# GD32H77x_78x register map
File version: 1.0
CPU: CM7 r1p2, little endian, MPU, FPU, 4 interrupt priority bits
Registers are 32-bit, read-write, reset 0x0 unless marked. A register's access mark holds for its fields unless they carry their own. Offsets are from the block's base; [hi:lo] are bit positions; {n}, {i} and the like mark numbered series.

## DBG — Debug
Base 0xE00E1000
0x00 ID ro — ID code register
  [31:0] ID_CODE — DBG ID code register
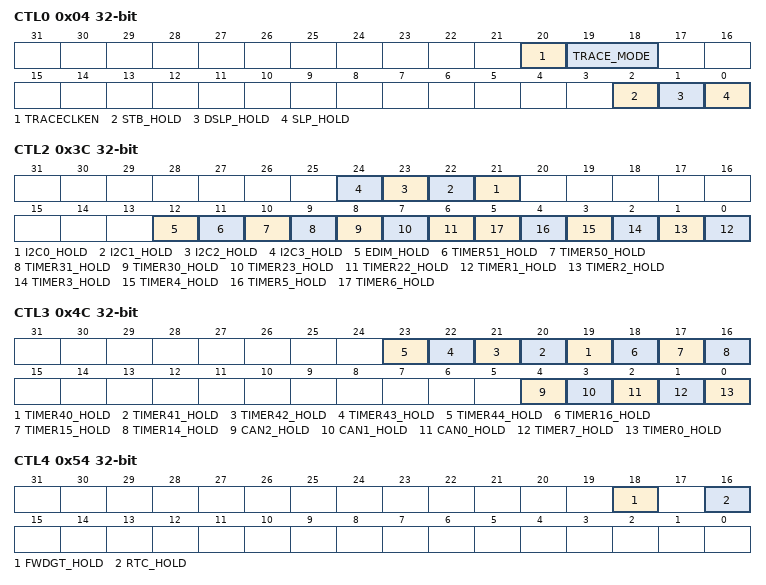
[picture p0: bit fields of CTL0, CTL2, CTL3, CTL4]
0x04 CTL0 — Control register0
  [20] TRACECLKEN — Trace port clock enable
  [19:18] TRACE_MODE — Trace pin allocation mode
  [2] STB_HOLD — Standby mode hold bit
  [1] DSLP_HOLD — Deep-sleep mode hold bit
  [0] SLP_HOLD — Sleep mode hold bit
0x34 CTL1 — Control register1
  [6] WWDGT_HOLD — WWDGT hold bit
0x3C CTL2 — Control register2
  [n+21] I2C{n}_HOLD (n=0..3) — I2C{n} hold bit
  [12] EDIM_HOLD — EDIM hold bit
  [11] TIMER51_HOLD — TIMER51 hold bit
  [10] TIMER50_HOLD — TIMER50 hold bit
  [9] TIMER31_HOLD — TIMER31 hold bit
  [8] TIMER30_HOLD — TIMER30 hold bit
  [7] TIMER23_HOLD — TIMER23 hold bit
  [6] TIMER22_HOLD — TIMER22 hold bit
  [n-1] TIMER{n}_HOLD (n=1..6) — TIMER{n} hold bit
0x4C CTL3 — Control register3
  [n-21] TIMER{n}_HOLD (n=40..44) — TIMER{n} hold bit
  [18] TIMER16_HOLD — TIMER16 hold bit
  [17] TIMER15_HOLD — TIMER15 hold bit
  [16] TIMER14_HOLD — TIMER14 hold bit
  [4] CAN2_HOLD — CAN2 hold bit
  [3] CAN1_HOLD — CAN1 hold bit
  [2] CAN0_HOLD — CAN0 hold bit
  [1] TIMER7_HOLD — TIMER7 hold bit
  [0] TIMER0_HOLD — TIMER0 hold bit
0x54 CTL4 — Control register4
  [18] FWDGT_HOLD — FWDGT hold bit
  [16] RTC_HOLD — RTC hold bit

## DCI — Digital Camera Interface
Base 0x48020000
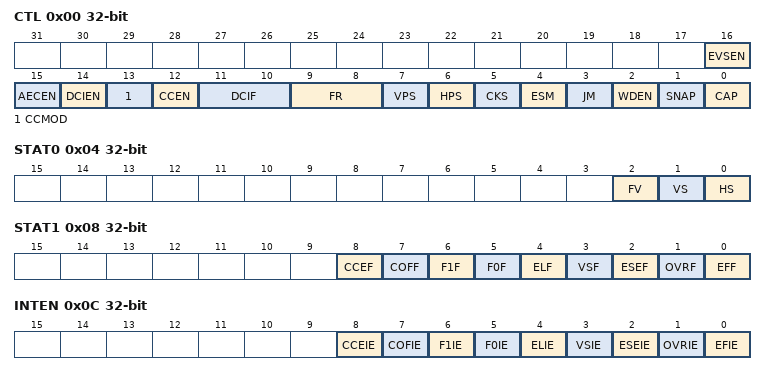
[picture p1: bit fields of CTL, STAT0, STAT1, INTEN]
0x00 CTL — Control register
  [16] EVSEN — External vsync enable
  [15] AECEN — Automatic error correction enable
  [14] DCIEN — DCI Enable
  [13] CCMOD — CCIR mode select
  [12] CCEN — CCIR enable
  [11:10] DCIF — Digital camera interface format
  [9:8] FR — Frame rate
  [7] VPS — Vertical Polarity Selection
  [6] HPS — Horizontal Polarity Selection
  [5] CKS — Clock Polarity Selection
  [4] ESM — Embedded Synchronous Mode
  [3] JM — JPEG mode
  [2] WDEN — Window Enable
  [1] SNAP — Snapshot mode
  [0] CAP — Capture Enable
0x04 STAT0 ro — Status register 0
  [2] FV — FIFO Valid
  [1] VS — VS line status
  [0] HS — HS line status
0x08 STAT1 ro — Status register 1
  [8] CCEF — CCIR error flag
  [7] COFF — CCIR change of field flag
  [6] F1F — CCIR field 1
  [5] F0F — CCIR field 0
  [4] ELF — End of Line Flag
  [3] VSF — Vsync Flag
  [2] ESEF — Embedded Synchronous Error Flag
  [1] OVRF — FIFO Overrun Flag
  [0] EFF — End of Frame Flag
0x0C INTEN — Interrupt enable register
  [8] CCEIE — CCIR error Interrupt enable
  [7] COFIE — CCIR change of field interrupt enable
  [6] F1IE — CCIR field 1 interrupt enable
  [5] F0IE — CCIR field 0 interrupt enable
  [4] ELIE — End of Line Interrupt Enable
  [3] VSIE — Vsync Interrupt Enable
  [2] ESEIE — Embedded Synchronous Error Interrupt Enable
  [1] OVRIE — FIFO Overrun Interrupt Enable
  [0] EFIE — End of Frame Interrupt Enable
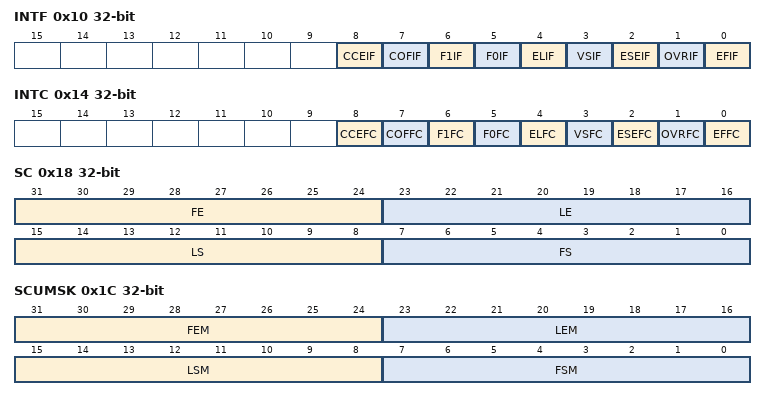
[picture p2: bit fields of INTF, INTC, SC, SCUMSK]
0x10 INTF ro — Interrupt flag register
  [8] CCEIF — CCIR error interrupt flag
  [7] COFIF — CCIR change of field interrupt flag
  [6] F1IF — CCIR field 1 interrupt flag
  [5] F0IF — CCIR field 0 interrupt flag
  [4] ELIF — End of Line Interrupt Flag
  [3] VSIF — Vsync Interrupt Flag
  [2] ESEIF — Embedded Synchronous Error Interrupt Flag
  [1] OVRIF — FIFO Overrun Interrupt Flag
  [0] EFIF — End of Frame Interrupt Flag
0x14 INTC wo — Interrupt flag clear register
  [8] CCEFC — CCIR error flag clear
  [7] COFFC — CCIR change of field flag clear
  [6] F1FC — CCIR field 1 interrupt flag clear
  [5] F0FC — CCIR field 0 interrupt flag clear
  [4] ELFC — End of Line Flag Clear
  [3] VSFC — Vsync flag clear
  [2] ESEFC — Clear embedded synchronous Error Flag
  [1] OVRFC — Clear FIFO Overrun Flag
  [0] EFFC — Clear End of Frame Flag
0x18 SC — Synchronization codes register
  [31:24] FE — Frame End Code in Embedded Synchronous Mode
  [23:16] LE — Line End Code in Embedded Synchronous Mode
  [15:8] LS — Line Start Code in Embedded Synchronous Mode
  [7:0] FS — Frame Start Code in Embedded Synchronous Mode
0x1C SCUMSK — Synchronization codes unmask register
  [31:24] FEM — Frame End Code unMask Bits in Embedded Synchronous Mode
  [23:16] LEM — Line End Code unMask Bits in Embedded Synchronous Mode
  [15:8] LSM — Line Start Code unMask Bits in Embedded Synchronous Mode
  [7:0] FSM — Frame Start Code unMask Bits in Embedded Synchronous Mode
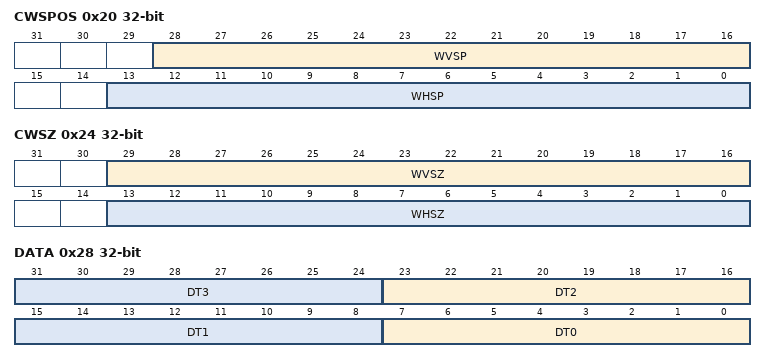
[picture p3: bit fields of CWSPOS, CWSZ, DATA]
0x20 CWSPOS — Cropping window start position register
  [28:16] WVSP — Window Vertical Start Position
  [13:0] WHSP — Window Horizontal Start Position
0x24 CWSZ — Cropping window size register
  [29:16] WVSZ — Window Vertical Size
  [13:0] WHSZ — Window Horizontal Size
0x28 DATA ro
  [8n+7:8n] DT{n} (n=0..3) — Pixel Data {n}
